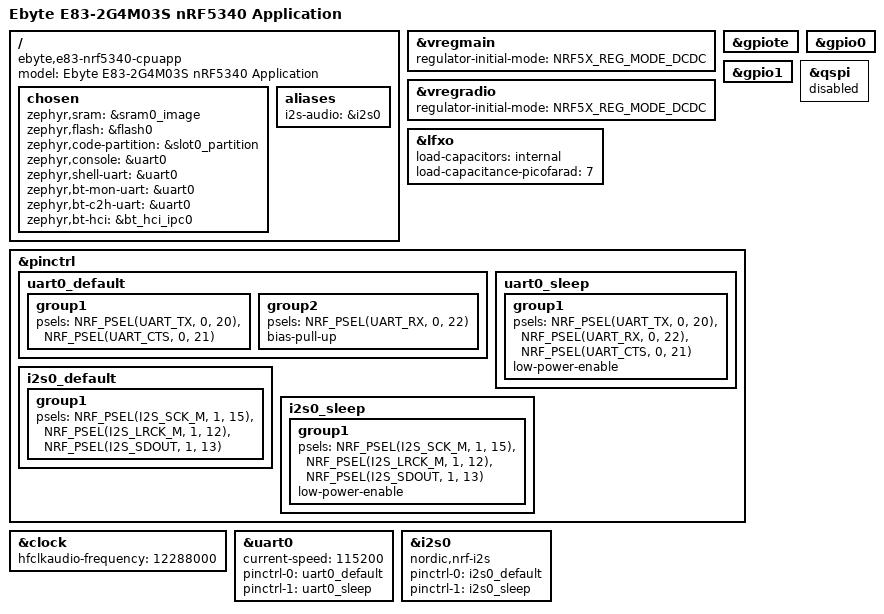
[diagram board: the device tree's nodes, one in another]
/dts-v1/;
#include <nordic/nrf5340_cpuapp_qkaa.dtsi>

/ {
	model = "Ebyte E83-2G4M03S nRF5340 Application";
	compatible = "ebyte,e83-nrf5340-cpuapp";

	chosen {
		zephyr,sram = &sram0_image;
		zephyr,flash = &flash0;
		zephyr,code-partition = &slot0_partition;
		zephyr,console = &uart0;
		zephyr,shell-uart = &uart0;
		zephyr,bt-mon-uart = &uart0;
		zephyr,bt-c2h-uart = &uart0;
		zephyr,bt-hci = &bt_hci_ipc0;
	};

	aliases {
		i2s-audio = &i2s0;
	};
};

&vregmain { regulator-initial-mode = <NRF5X_REG_MODE_DCDC>; };
&vregradio { regulator-initial-mode = <NRF5X_REG_MODE_DCDC>; };
&lfxo {
	load-capacitors = "internal";
	load-capacitance-picofarad = <7>;
};

&gpiote { status = "okay"; };
&gpio0 { status = "okay"; };
&gpio1 { status = "okay"; };

&pinctrl {
	/* UART0 remapped to E83-2G4M03S-TB CH340X wiring:
	 * TX=P0.20, RX=P0.22, CTS=P0.21 (no RTS — CH340X 3-wire).
	 */
	uart0_default: uart0_default {
		group1 {
			psels = <NRF_PSEL(UART_TX, 0, 20)>,
				<NRF_PSEL(UART_CTS, 0, 21)>;
		};
		group2 {
			psels = <NRF_PSEL(UART_RX, 0, 22)>;
			bias-pull-up;
		};
	};
	uart0_sleep: uart0_sleep {
		group1 {
			psels = <NRF_PSEL(UART_TX, 0, 20)>,
				<NRF_PSEL(UART_RX, 0, 22)>,
				<NRF_PSEL(UART_CTS, 0, 21)>;
			low-power-enable;
		};
	};

	/* I2S0 to CJMCU-1334 (UDA1334A): BCK=P1.15, DIN=P1.13, LRCK=P1.12 */
	i2s0_default: i2s0_default {
		group1 {
			psels = <NRF_PSEL(I2S_SCK_M, 1, 15)>,
				<NRF_PSEL(I2S_LRCK_M, 1, 12)>,
				<NRF_PSEL(I2S_SDOUT, 1, 13)>;
		};
	};
	i2s0_sleep: i2s0_sleep {
		group1 {
			psels = <NRF_PSEL(I2S_SCK_M, 1, 15)>,
				<NRF_PSEL(I2S_LRCK_M, 1, 12)>,
				<NRF_PSEL(I2S_SDOUT, 1, 13)>;
			low-power-enable;
		};
	};
};

&clock {
	hfclkaudio-frequency = <12288000>;
};

&uart0 {
	status = "okay";
	current-speed = <115200>;
	pinctrl-0 = <&uart0_default>;
	pinctrl-1 = <&uart0_sleep>;
	pinctrl-names = "default", "sleep";
};

&i2s0 {
	compatible = "nordic,nrf-i2s";
	status = "okay";
	pinctrl-0 = <&i2s0_default>;
	pinctrl-1 = <&i2s0_sleep>;
	pinctrl-names = "default", "sleep";
};

/* E83 module has no external QSPI flash */
&qspi {
	status = "disabled";
};

/* Include default memory partition configuration (mcuboot, slot0/1, storage) */
#include <nordic/nrf5340_cpuapp_partition.dtsi>
